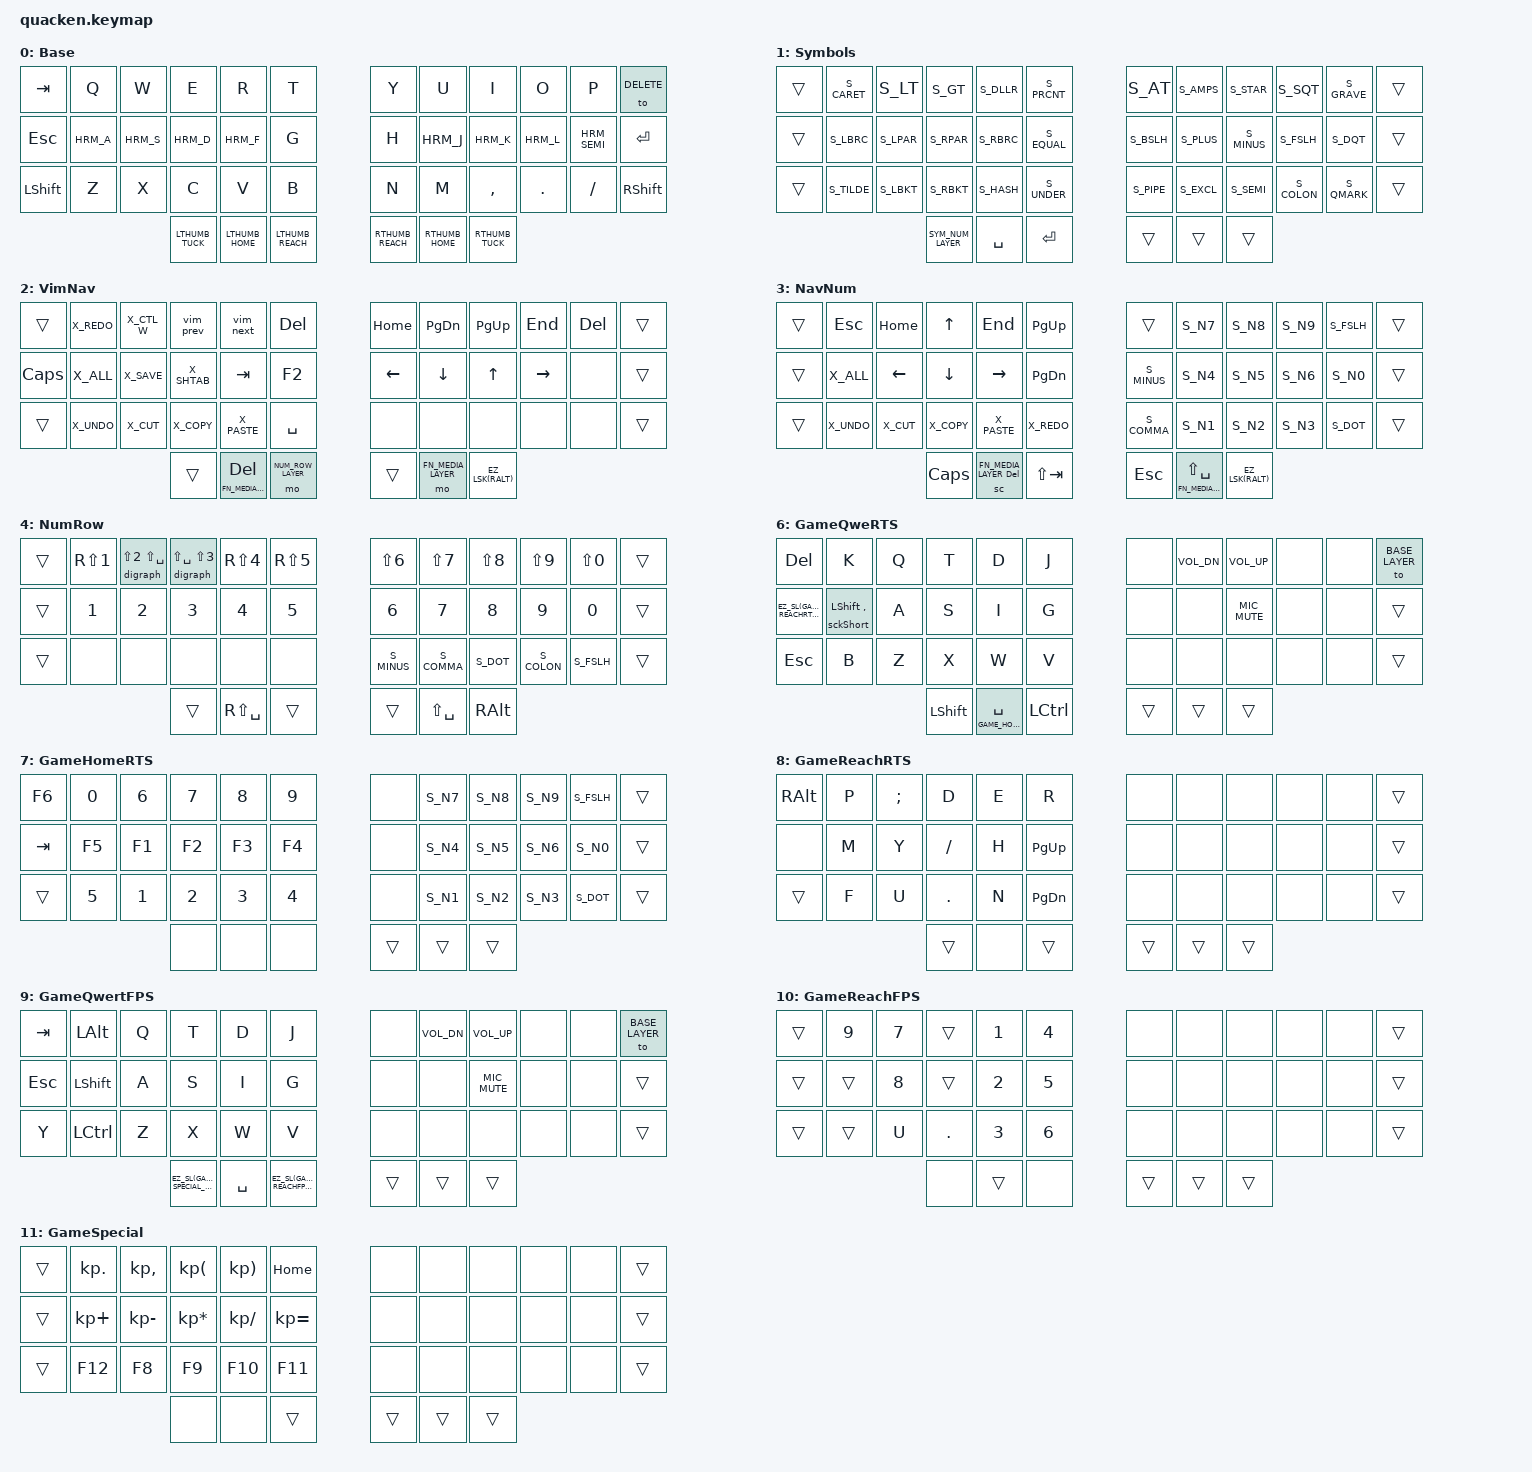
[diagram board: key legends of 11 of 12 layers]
// Selenium keymap:
// https://github.com/OneDeadKey/selenium

#ifndef CI_IGNORE_USER_SETTINGS
  #include "settings.h"   // user settings, ignored by CI tests
#endif

#include "aliases.h"      // symbols, actions, non-ASCII chars
#include "mappings.dtsi"  // key mapping helpers and macros
#include "hold_taps.dtsi" // thumb keys and homerow mods

{
keymap {
  compatible = "zmk,keymap";

  // 0. Base layer -- keep the QWERTY key codes to use your OS keyboard layout
  //               -- the Space Cadet layer-tap on the right can be replaced by an AltGr/Enter mod-tap
  //               -- adjust the homerow mods with the #define statements above
  base_layer: base_layer {
    display-name = "Base";
    bindings = <
      &kp TAB    &kp Q  &kp W  &kp E  &kp R  &kp T        &kp Y  &kp U  &kp I     &kp O   &kp P      &to DELETE
      &kp ESCAPE HRM_A  HRM_S  HRM_D  HRM_F  &kp G        &kp H  HRM_J  HRM_K     HRM_L   HRM_SEMI   &kp ENTER
      &kp LSHIFT &kp Z  &kp X  &kp C  &kp V  &kp B        &kp N  &kp M  &kp COMMA &kp DOT &kp FSLH   &kp RSHIFT
              LTHUMB_TUCK  LTHUMB_HOME  LTHUMB_REACH    RTHUMB_REACH  RTHUMB_HOME  RTHUMB_TUCK
    >;
  };

  // 1. Symbols layer -- with Ergo-L, basically just an AltGr layer with custom thumb keys
  //                  -- can be redefined for non-AltGr layouts such as QWERTY-ANSI
  symbols_layer: symbols_layer {
		display-name = "Symbols";
    bindings = <
      &trans  S_CARET S_LT    S_GT    S_DLLR  S_PRCNT       S_AT    S_AMPS  S_STAR  S_SQT   S_GRAVE  &trans
      &trans  S_LBRC  S_LPAR  S_RPAR  S_RBRC  S_EQUAL       S_BSLH  S_PLUS  S_MINUS S_FSLH  S_DQT    &trans
      &trans  S_TILDE S_LBKT  S_RBKT  S_HASH  S_UNDER       S_PIPE  S_EXCL  S_SEMI  S_COLON S_QMARK  &trans
                  SYM_NUM_LAYER  &kp SPACE  &kp ENTER       &trans  &trans  &trans
    >;
  };

  // 2. VimNav layer -- HJKL arrow cluster o_n the right hand
  //                 -- best used along with the NumRow layer
  //                 -- keyboard shortcuts on the left hand are adjusted to the OS layout (Ergo-L here)
  vim_nav_layer: vim_nav_layer {
    display-name = "VimNav";
    bindings = <
      &trans   X_REDO    X_CTL_W  &vim_prev &vim_next &kp DEL       &kp HOME &kp PG_DN &kp PG_UP &kp END   &kp DEL &trans
      &kp CAPS X_ALL     X_SAVE   X_SHTAB   &kp TAB   &kp F2        &kp LEFT &kp DOWN  &kp UP    &kp RIGHT &none   &trans
      &trans   X_UNDO    X_CUT    X_COPY    X_PASTE   &kp SPACE     &none    &none     &none     &none     &none   &trans
           &trans   &lt FN_MEDIA_LAYER DEL  &mo NUM_ROW_LAYER       &trans  &mo FN_MEDIA_LAYER  &EZ_LSK(RALT)
    >;
  };

  // 3. NavNum layer -- inverted T arrow cluster on the left hand, numpad on the right hand
  //                 -- can be the only extra layer you need if you're not too picky with number+symbols n-grams
  //                 -- keyboard shortcuts on the left hand are adjusted to the OS layout (Ergo-L here)
  nav_num_layer: nav_num_layer {
    display-name = "NavNum";
    bindings = <
      &trans  &kp ESC  &kp HOME &kp UP   &kp END   &kp PG_UP    &trans             S_N7  S_N8  S_N9  S_FSLH  &trans
      &trans  X_ALL    &kp LEFT &kp DOWN &kp RIGHT &kp PG_DN    S_MINUS            S_N4  S_N5  S_N6  S_N0    &trans
      &trans  X_UNDO   X_CUT    X_COPY   X_PASTE   X_REDO       S_COMMA            S_N1  S_N2  S_N3  S_DOT   &trans
               &kp CAPS  &sc FN_MEDIA_LAYER DEL  &kp LS(TAB)    &kp ESCAPE  &lt FN_MEDIA_LAYER LS(SPACE)  &EZ_LSK(RALT)
    >;
  };

	// 4. NumRow layer -- bring the numbers to the homerow, keep shift+numbers for shortcuts and symbols
	//                 -- space becomes shift+space, which is a no-break space with some OS layouts (e.g. Ergo-L)
	//                 -- best used along with the VimNav layer
	num_row_layer: num_row_layer {
		display-name = "NumRow";
		bindings = <
			&trans  &kp RS(N1) &digraph LS(N2) LS(SPC) &digraph LS(SPC) LS(N3) &kp RS(N4) &kp RS(N5)       &kp LS(N6) &kp LS(N7) &kp LS(N8) &kp LS(N9) &kp LS(N0) &trans
			&trans  &kp N1     &kp N2     &kp N3     &kp N4     &kp N5           &kp N6     &kp N7     &kp N8     &kp N9     &kp N0     &trans
			&trans  &none      &none      &none      &none      &none            S_MINUS    S_COMMA    S_DOT      S_COLON    S_FSLH     &trans
			&trans  &kp RS(SPACE) &trans           &trans  &kp LS(SPACE) &kp RALT
		>;
	};

	// 5. FnMedia layer -- F1..12 pad on the left hand, HRM on the right hand
	//                  -- reset and bootloader reset on difficult thumb keys
	//                  -- could be completed with other rare keys, changed volume up down and next/prev media to follow vim motions
	fn_media_layer: fn_media_layer {
		display-name = "FnMedia";
		bindings = <
			&trans  &kp F1  &kp F2  &kp F3  &kp F4  &none         H_L C_AL_LOCK  &kp C_VOL_DN  &kp C_VOL_UP &kp C_BRI_UP   &kp SLCK      &to GAME_QWERTS_LAYER
			&trans  &kp F5  &kp F6  &kp F7  &kp F8  &none         &kp C_PREV     H_J C_PP      H_K C_MUTE   &kp C_NEXT     H_SEMI PSCRN  &to GAME_QWERTFPS_LAYER
			&trans  &kp F9  &kp F10 &kp F11 &kp F12 &none         &none          &none         &none        &kp C_BRI_DN   &kp INS       &trans
			&trans  &trans  &bootloader   &sys_reset  &trans  &studio_unlock
		>;
	};

	// 6. Game qwerty emulation layer, aimed at RTS (specifically for aoe4)
	//																rotation of qwert towards the inside
	//																goal is to offer as many viable keys under left hand with layers
	//																rotation is due to high 4th finger usage in aoe4 grid key system, 5th finger gets the less commonly used keys
	game_qweRTS_layer: game_qweRTS_layer {
		display-name = "GameQweRTS";
		bindings = <
			&kp DEL                        &kp K               &kp Q &kp T   &kp D   &kp J                 &none    &kp C_VOL_DN &kp C_VOL_UP    &none &none   &to BASE_LAYER
			&EZ_SL(GAME_REACHRTS_LAYER)    &sckShort LSHIFT COMMA   &kp A &kp S   &kp I   &kp G            &none    &none        &kp C_MIC_MUTE  &none &none   &trans
			&kp ESCAPE                     &kp B               &kp Z &kp X   &kp W   &kp V                 &none    &none        &none           &none &none   &trans
	                               &kp LSHIFT &lt GAME_HOMERTS_LAYER SPACE   &kp LCTL                  &trans  &trans  &trans
		>;
	};

	// 7. QWERTS Thumb Home layer, preserve tab and shift tab from nav layer for muscle memory, useful in rts selection cycling
	game_homeRTS_layer: game_homeRTS_layer {
		display-name = "GameHomeRTS";
		bindings = <
			&kp F6  &kp N0     &kp N6     &kp N7       &kp N8     &kp N9         &none    S_N7  S_N8  S_N9  S_FSLH   &trans
			&kp TAB &kp F5     &kp F1     &kp F2       &kp F3     &kp F4         &none    S_N4  S_N5  S_N6  S_N0     &trans
			&trans  &kp N5     &kp N1     &kp N2       &kp N3     &kp N4         &none    S_N1  S_N2  S_N3  S_DOT    &trans
		                                           &none  &none  &none         &trans  &trans  &trans
		>;
	};

	// 8. QWERTS Thumb Reach layer -- Offer many new keys for potential rebinding
	game_reachRTS_layer: game_reachRTS_layer {
		display-name = "GameReachRTS";
		bindings = <
			&kp RALT &kp P  &kp SEMI  &kp D     &kp E   &kp R          &none    &none     &none     &none     &none   &trans
			&none    &kp M  &kp Y     &kp FSLH  &kp H   &kp PG_UP      &none    &none     &none     &none     &none   &trans
			&trans   &kp F  &kp U     &kp DOT   &kp N   &kp PG_DN      &none    &none     &none     &none     &none   &trans
                                       &trans &none  &trans      &trans  &trans  &trans
		>;
	};

	// 9. GameQwertFPS layer -- Offset of partial QWERTY emulation
	//													Commonly used modifier keys moved to 5th finger position
	//													Symbol layer as a sticky to access more one off keys for rarer hotkeys
	game_qwertFPS_layer: game_qwertFPS_layer {
		display-name = "GameQwertFPS";
		bindings = <
			&kp TAB     &kp LALT  &kp Q &kp T   &kp D   &kp J                 &none    &kp C_VOL_DN &kp C_VOL_UP     &none     &none   &to BASE_LAYER
			&kp ESCAPE  &kp LSHFT &kp A &kp S   &kp I   &kp G                 &none    &none        &kp C_MIC_MUTE   &none     &none   &trans
			&kp Y       &kp LCTL  &kp Z &kp X   &kp W   &kp V                 &none    &none        &none						 &none     &none   &trans
			&EZ_SL(GAME_SPECIAL_LAYER) &kp SPACE  &EZ_SL(GAME_REACHFPS_LAYER)          &trans  &trans  &trans
		>;
	};

	// 10. Game reach fps layer with some transparent keys to allow for some movement while held
	//													Access to number keys for inventory switching, common hotkey in games
	//													Can still access modifiers and tab with 5th finger
  game_reachFPS_layer: game_reachFPS_layer {
    display-name = "GameReachFPS";
    bindings = <
      &trans  &kp N9     &kp N7    &trans     &kp N1  &kp N4         &none    &none     &none     &none     &none   &trans
      &trans  &trans     &kp N8    &trans     &kp N2  &kp N5         &none    &none     &none     &none     &none   &trans
      &trans  &trans     &kp U     &kp DOT    &kp N3  &kp N6         &none    &none     &none     &none     &none   &trans
                                          &none &trans &none         &trans  &trans  &trans
    >;
  };

	// 11. Game special layer which disregard the ability to hold fps base keys to instead offer rarer additional keys
  game_special_layer: game_special_layer {
    display-name = "GameSpecial";
    bindings = <
      &trans  &kp KP_DOT  &kp KP_COMMA   &kp KP_LPAR      &kp KP_RPAR    &kp HOME           &none    &none     &none     &none     &none   &trans
      &trans  &kp KP_PLUS &kp KP_MINUS   &kp KP_MULTIPLY  &kp KP_DIVIDE  &kp KP_EQUAL       &none    &none     &none     &none     &none   &trans
      &trans  &kp F12     &kp F8         &kp F9           &kp F10        &kp F11            &none    &none     &none     &none     &none   &trans
                                                             &none &none  &trans            &trans  &trans  &trans
    >;
  };

	};
};

#include "aliases.h"      // symbols, actions, non-ASCII chars
#include "mappings.dtsi"  // key mapping helpers and macros
#include "hold_taps.dtsi" // thumb keys and homerow mods


// Emulated layouts (experimental!)
#ifdef KB_EMULATION_DVORAK
  #include "emulations/dvorak.dtsi"
#elif defined KB_EMULATION_ERGOL
  #include "emulations/ergol.dtsi"
#elif defined KB_EMULATION_QWERTY_LAFAYETTE
  #include "emulations/qwerty_lafayette.dtsi"

// Some layouts require extra layers to fit on the Quacken.
#elif defined KB_LAYOUT_AZERTY
  #include "extra_layers/azerty.dtsi"
#elif defined KB_LAYOUT_BEPO
  #include "extra_layers/bepo.dtsi"
#elif defined KB_LAYOUT_ERGOL && defined HUMMINGBIRD
  #include "extra_layers/ergol_hummingbird.dtsi"
#endif
